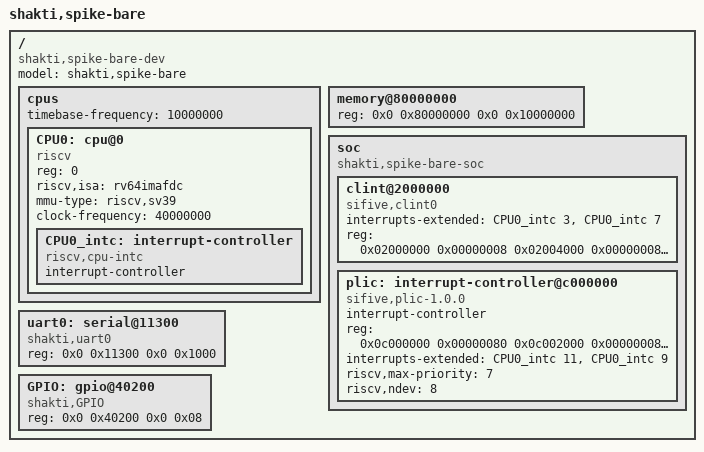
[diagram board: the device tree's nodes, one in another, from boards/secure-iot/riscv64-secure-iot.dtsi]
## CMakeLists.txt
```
# SPDX-License-Identifier: Apache-2.0

cmake_minimum_required(VERSION 3.20.0)
find_package(Zephyr REQUIRED HINTS $ENV{ZEPHYR_BASE})
project(gpio_testcase)

# FILE(GLOB app_sources src/*.c)
target_sources(app PRIVATE src/main.c)
```

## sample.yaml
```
sample:
  description: gpio_test sample, the simplest Zephyr
    application
  name: gpio_testcase
common:
    tags: introduction
    integration_platforms:
      - native_posix
    harness: console
    harness_config:
      type: few lines
      regex:
        - "(.*)"
tests:
  sample.basic.gpio_testcase:
    tags: introduction
```

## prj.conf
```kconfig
# nothing here
#GPIO_SHAKTI=y
```

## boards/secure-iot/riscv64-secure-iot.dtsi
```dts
/ {
#address-cells = <2>;
#size-cells = <2>;
  compatible = "shakti,spike-bare-dev";
  model = "shakti,spike-bare";
  cpus {
#address-cells = <1>;
#size-cells = <0>;
    timebase-frequency = <10000000>;
CPU0: cpu@0 {
        device_type = "cpu";
        reg = <0>;
        status = "okay";
        compatible = "riscv";
        riscv,isa = "rv64imafdc";
        mmu-type = "riscv,sv39";
        clock-frequency = <40000000>;
CPU0_intc: interrupt-controller {
             #address-cells = <0>;
	           #interrupt-cells = <1>;
             interrupt-controller;
             compatible = "riscv,cpu-intc";
           };
      };
  };
  memory@80000000 {
    device_type = "memory";
    reg = <0x0 0x80000000 0x0 0x10000000 >;
  };
  soc {
    #address-cells = <1>;
		#size-cells = <1>;
    compatible = "shakti,spike-bare-soc", "simple-bus";
    ranges;
    clint@2000000 {
      #address-cells = <0>;
      #size-cells = <2>;
      compatible = "sifive,clint0";
      interrupts-extended = <&CPU0_intc 3 &CPU0_intc 7 >;
      reg = <0x02000000 0x00000008
            0x02004000 0x00000008
	    0x0200bff8 0x00000008>;
    };
    plic: interrupt-controller@c000000 {
      #address-cells = <0>;
			#interrupt-cells = <2>;
      compatible = "sifive,plic-1.0.0";
      interrupt-controller;
      reg = <0x0c000000 0x00000080
			       0x0c002000 0x00000008
			       0x0c200000 0x00001000>;
			reg-names = "prio", "irq_en", "reg";
      interrupts-extended = <&CPU0_intc 11 &CPU0_intc 9>; //11 as to mention MACHINE MODE for CPU or 9 for SUPERVISOR MODE for CPU...
      riscv,max-priority = <7>;
      riscv,ndev = <8>;
    };
  };

uart0: serial@11300 {
         compatible = "shakti,uart0";
         reg= < 0x0 0x11300 0x0 0x1000>;
  };

GPIO: gpio@40200 {
          compatible = "shakti,GPIO";
          reg = < 0x0 0x40200 0x0 0x08>;
  };
};
```

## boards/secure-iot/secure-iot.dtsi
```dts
/dts-v1/;

#include <riscv64-secure-iot.dtsi>

/ {
	model = "shakti,spike-bare";
	compatible = "shakti,spike-bare-dev";

chosen {
		zephyr,console = &uart0;
		zephyr,console = &GPIO
	};


};

&uart0 {
	status = "okay";
	current-speed = <19200>;
	clock-frequency = <40000000>;
};

&GPIO {
	status = "okay";
};
```

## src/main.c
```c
//#include "/home/kishore/work/zephyrproject/zephyr/include/zephyr/drivers/gpio/gpio_shakti.h"

#include <zephyr/kernel.h>
//#include "zephyr/gpio_shakti.h"
#include "/home/kishore/work/zephyr/drivers/gpio/gpio_shakti.c"

#define GPIO_OUTPUT 1
#define GPIO0  (1 <<  0)
#define GPIO1  (1 <<  1)


void main(){
    
    const struct device *dev;
    printk("*******Hello World!******** %s\n", CONFIG_ARCH);
    gpio_shakti_init(dev);
    printk("*******Hello World!******** %s\n", CONFIG_ARCH);
    gpio_shakti_pin_configure(dev, GPIO0, GPIO_OUTPUT);
    gpio_shakti_pin_configure(dev, GPIO1, GPIO_OUTPUT);

    while(1){
        gpio_shakti_pin_set_raw(dev, GPIO0, 1);
        gpio_shakti_pin_set_raw(dev, GPIO1, 1);
        
        for (int i=0; i<20; i++){}
        
        gpio_shakti_pin_clear_raw(dev, GPIO0);
        gpio_shakti_pin_clear_raw(dev, GPIO1);
    }
}
```
